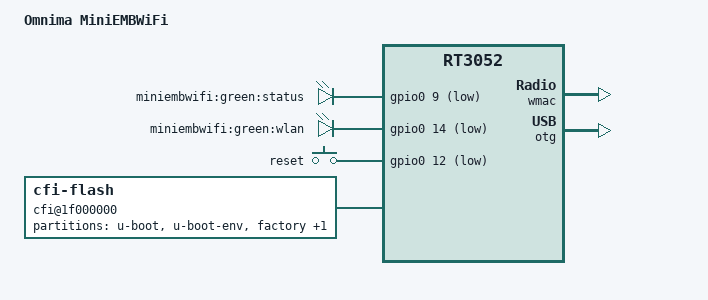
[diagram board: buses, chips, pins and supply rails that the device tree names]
/dts-v1/;

#include "rt3050.dtsi"

/ {
	compatible = "MINIEMBWIFI", "ralink,rt3052-soc";
	model = "Omnima MiniEMBWiFi";

	gpio-leds {
		compatible = "gpio-leds";

		status {
			label = "miniembwifi:green:status";
			gpios = <&gpio0 9 1>;
		};

		wlan {
			label = "miniembwifi:green:wlan";
			gpios = <&gpio0 14 1>;
		};
	};

	gpio-keys-polled {
		compatible = "gpio-keys-polled";
		#address-cells = <1>;
		#size-cells = <0>;
		poll-interval = <20>;

		reset {
			label = "reset";
			gpios = <&gpio0 12 1>;
			linux,code = <0x198>;
		};
	};

	cfi@1f000000 {
		compatible = "cfi-flash";
		reg = <0x1f000000 0x800000>;
		bank-width = <2>;
		device-width = <2>;
		#address-cells = <1>;
		#size-cells = <1>;

		partition@0 {
			label = "u-boot";
			reg = <0x0 0x30000>;
			read-only;
		};

		partition@30000 {
			label = "u-boot-env";
			reg = <0x30000 0x10000>;
			read-only;
		};

		factory: partition@40000 {
			label = "factory";
			reg = <0x40000 0x10000>;
			read-only;
		};

		partition@50000 {
			label = "firmware";
			reg = <0x50000 0x7b0000>;
		};
	};
};

&pinctrl {
	state_default: pinctrl0 {
		gpio {
			ralink,group = "spi", "i2c", "jtag", "rgmii", "mdio", "uartf";
			ralink,function = "gpio";
		};
	};
};

&ethernet {
	mtd-mac-address = <&factory 0x28>;
};

&esw {
	mediatek,portmap = <0x2f>;
};

&wmac {
	ralink,mtd-eeprom = <&factory 0>;
};

&otg {
	status = "okay";
};
